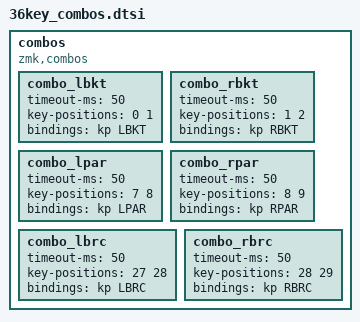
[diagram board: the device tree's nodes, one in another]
/*                              36 KEY MATRIX / LAYOUT MAPPING

  ╭────────────────────┬────────────────────╮ ╭─────────────────────┬─────────────────────╮
  │  0   1   2   3   4 │  5   6   7   8   9 │ │ LT4 LT3 LT2 LT1 LT0 │ RT0 RT1 RT2 RT3 RT4 │
  │ 10  11  12  13  14 │ 15  16  17  18  19 │ │ LM4 LM3 LM2 LM1 LM0 │ RM0 RM1 RM2 RM3 RM4 │
  │ 20  21  22  23  24 │ 25  26  27  28  29 │ │ LB4 LB3 LB2 LB1 LB0 │ RB0 RB1 RB2 RB3 RB4 │
  ╰───────╮ 30  31  32 │ 33  34  35 ╭───────╯ ╰───────╮ LH2 LH1 LH0 │ RH0 RH1 RH2 ╭───────╯
          ╰────────────┴────────────╯                 ╰─────────────┴─────────────╯             */

combos {
  compatible = "zmk,combos";
  combo_lbkt {
    timeout-ms = <50>;
    key-positions = <0 1>;
    bindings = <&kp LBKT>;
  };
  combo_rbkt {
    timeout-ms = <50>;
    key-positions = <1 2>;
    bindings = <&kp RBKT>;
  };
  combo_lpar {
    timeout-ms = <50>;
    key-positions = <7 8>;
    bindings = <&kp LPAR>;
  };
  combo_rpar {
    timeout-ms = <50>;
    key-positions = <8 9>;
    bindings = <&kp RPAR>;
  };
  combo_lbrc {
    timeout-ms = <50>;
    key-positions = <27 28>;
    bindings = <&kp LBRC>;
  };
  combo_rbrc {
    timeout-ms = <50>;
    key-positions = <28 29>;
    bindings = <&kp RBRC>;
  };
}; 
